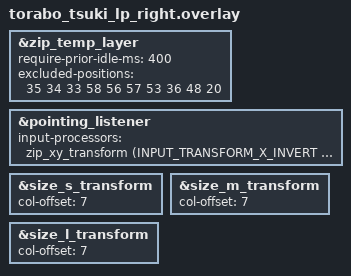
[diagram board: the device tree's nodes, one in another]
#include "torabo_tsuki_lp.dtsi"
#include <input/processors.dtsi>
#include <dt-bindings/zmk/input_transform.h>

// AML用の設定
&zip_temp_layer {
    // AML on のしきい値(ms)
    require-prior-idle-ms = <400>;
    // mouse click keys (key番号はCOMBOで確認可能)
    // excluded-positions =  <35 34 33 58 56 19 21 20 48 47 49 57 53 25>;
    excluded-positions = <35 34 33 58 56 57 53 36 48 20>;
};

&pointing_listener {
    // AML無し設定
    input-processors = <&zip_xy_transform (INPUT_TRANSFORM_X_INVERT | INPUT_TRANSFORM_Y_INVERT)>;

    // AML有り設定  ($zip_temp_layer <layer_num> <timeout[ms]>)
    /*
    input-processors = <
        &zip_xy_transform (INPUT_TRANSFORM_X_INVERT | INPUT_TRANSFORM_Y_INVERT)
        &zip_temp_layer 1 1000
    >;
    */
    
};

&size_s_transform {
    col-offset = <7>;
};

&size_m_transform {
    col-offset = <7>;
};

&size_l_transform {
    col-offset = <7>;
};
